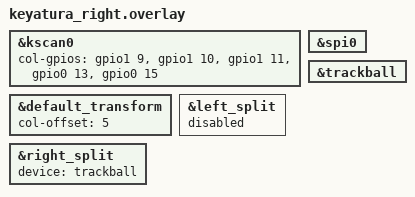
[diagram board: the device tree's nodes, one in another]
#include "keyatura.dtsi"
#include "trackball.dtsi"

&kscan0 {
    col-gpios
        = <&gpio1 9 GPIO_ACTIVE_HIGH>
        , <&gpio1 10 GPIO_ACTIVE_HIGH>
        , <&gpio1 11 GPIO_ACTIVE_HIGH>
        , <&gpio0 13 GPIO_ACTIVE_HIGH>
        , <&gpio0 15 GPIO_ACTIVE_HIGH>
        ;
};

&default_transform {
	col-offset = <5>;
};

&spi0 {
    status = "okay";
};

&trackball {
    status = "okay";
};

&left_split {
    status = "disabled";
};

&right_split {
    device = <&trackball>;
};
